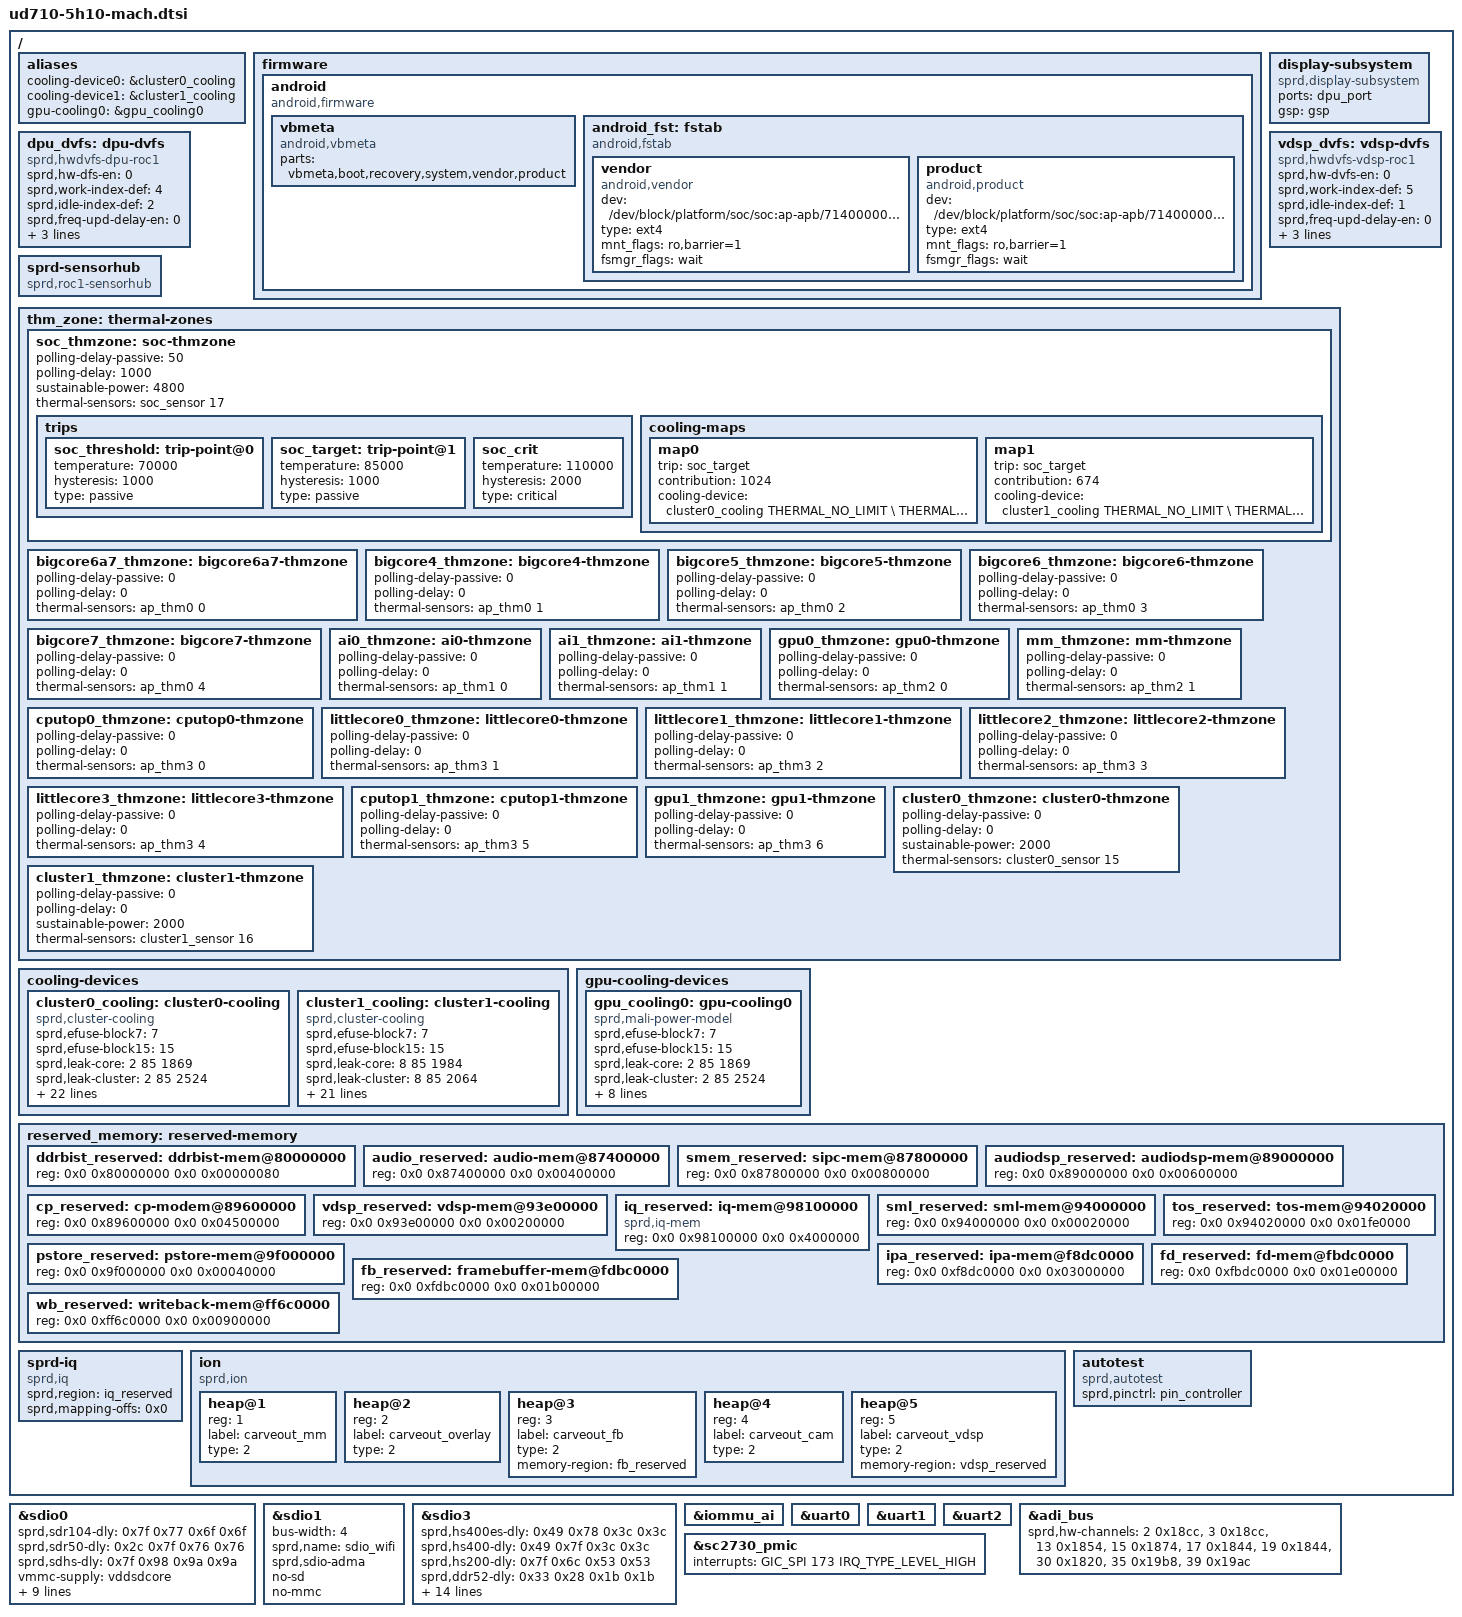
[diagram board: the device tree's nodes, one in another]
/*
 * Spreadtrum Roc1 board common DTS file
 *
 * Copyright (C) 2018, Spreadtrum Communications Inc.
 *
 * This file is licensed under a dual GPLv2 or X11 license.
 */

#include <dt-bindings/thermal/thermal.h>
/ {
	aliases {
		cooling-device0 = &cluster0_cooling;
		cooling-device1 = &cluster1_cooling;
		gpu-cooling0 = &gpu_cooling0;
	};

	firmware {
		android {
			compatible = "android,firmware";

			vbmeta {
				compatible = "android,vbmeta";
				parts = "vbmeta,boot,recovery,system,vendor,product";
			};

			android_fst: fstab {
				compatible = "android,fstab";
				vendor {
					compatible = "android,vendor";
					dev = "/dev/block/platform/soc/soc:ap-apb/71400000.sdio/by-name/vendor";
					type = "ext4";
					mnt_flags = "ro,barrier=1";
					fsmgr_flags = "wait";
				};
				product {
					compatible = "android,product";
					dev = "/dev/block/platform/soc/soc:ap-apb/71400000.sdio/by-name/product";
					type = "ext4";
					mnt_flags = "ro,barrier=1";
					fsmgr_flags = "wait";
				};
			};
		};
	};

	display-subsystem {
		compatible = "sprd,display-subsystem";
		ports = <&dpu_port>;
		gsp = <&gsp>;
	};

	dpu_dvfs: dpu-dvfs {
		compatible = "sprd,hwdvfs-dpu-roc1";
		sprd,hw-dfs-en = <0>;
		sprd,work-index-def = <4>;
		sprd,idle-index-def = <2>;
		sprd,freq-upd-delay-en = <0>;
		sprd,freq-upd-hdsk-en = <1>;

		operating-points = <
			/* kHz    uV */
			153600    700000
			192000    700000
			256000    700000
			307200    700000
			384000    750000
		>;
	};

	vdsp_dvfs: vdsp-dvfs {
		compatible = "sprd,hwdvfs-vdsp-roc1";
		sprd,hw-dvfs-en = <0>;
		sprd,work-index-def = <5>;
		sprd,idle-index-def = <1>;
		sprd,freq-upd-delay-en = <0>;
		sprd,freq-upd-hdsk-en = <1>;

		operating-points = <
			/* kHz    uV */
			192000    700000
			307200    700000
			468000    750000
			614400    800000
			702000    800000
			768000    800000
		>;
	};

	sprd-sensorhub {
		compatible = "sprd,roc1-sensorhub";
	};

	thm_zone: thermal-zones {

		soc_thmzone: soc-thmzone {
			polling-delay-passive = <50>;
			polling-delay = <1000>;
			sustainable-power = <4800>;
			thermal-sensors = <&soc_sensor  17>;
			trips {
				soc_threshold: trip-point@0 {
					temperature = <70000>;
					hysteresis = <1000>;
					type = "passive";
				};
				soc_target: trip-point@1 {
					temperature = <85000>;
					hysteresis = <1000>;
					type = "passive";
				};
				soc_crit: soc_crit {
					temperature = <110000>;
					hysteresis = <2000>;
					type = "critical";
				};
			};
			cooling-maps {
				map0 {
					trip = <&soc_target>;
					contribution = <1024>;
					cooling-device =
					<&cluster0_cooling THERMAL_NO_LIMIT \
					THERMAL_NO_LIMIT>;
				};
				map1 {
					trip = <&soc_target>;
					contribution = <674>;
					cooling-device =
					<&cluster1_cooling THERMAL_NO_LIMIT \
					THERMAL_NO_LIMIT>;
				};
			};
		};

		bigcore6a7_thmzone: bigcore6a7-thmzone {
			polling-delay-passive = <0>;
			polling-delay = <0>;
			thermal-sensors = <&ap_thm0 0>;
		};

		bigcore4_thmzone: bigcore4-thmzone {
			polling-delay-passive = <0>;
			polling-delay = <0>;
			thermal-sensors = <&ap_thm0 1>;
		};

		bigcore5_thmzone: bigcore5-thmzone {
			polling-delay-passive = <0>;
			polling-delay = <0>;
			thermal-sensors = <&ap_thm0 2>;
		};

		bigcore6_thmzone: bigcore6-thmzone {
			polling-delay-passive = <0>;
			polling-delay = <0>;
			thermal-sensors = <&ap_thm0 3>;
		};

		bigcore7_thmzone: bigcore7-thmzone {
			polling-delay-passive = <0>;
			polling-delay = <0>;
			thermal-sensors = <&ap_thm0 4>;
		};

		ai0_thmzone: ai0-thmzone {
			polling-delay-passive = <0>;
			polling-delay = <0>;
			thermal-sensors = <&ap_thm1 0>;
		};

		ai1_thmzone: ai1-thmzone {
			polling-delay-passive = <0>;
			polling-delay = <0>;
			thermal-sensors = <&ap_thm1 1>;
		};

		gpu0_thmzone: gpu0-thmzone {
			polling-delay-passive = <0>;
			polling-delay = <0>;
			thermal-sensors = <&ap_thm2 0>;
		};

		mm_thmzone: mm-thmzone {
			polling-delay-passive = <0>;
			polling-delay = <0>;
			thermal-sensors = <&ap_thm2 1>;
		};

		cputop0_thmzone: cputop0-thmzone {
			polling-delay-passive = <0>;
			polling-delay = <0>;
			thermal-sensors = <&ap_thm3 0>;
		};

		littlecore0_thmzone: littlecore0-thmzone {
			polling-delay-passive = <0>;
			polling-delay = <0>;
			thermal-sensors = <&ap_thm3 1>;
		};

		littlecore1_thmzone: littlecore1-thmzone {
			polling-delay-passive = <0>;
			polling-delay = <0>;
			thermal-sensors = <&ap_thm3 2>;
		};

		littlecore2_thmzone: littlecore2-thmzone {
			polling-delay-passive = <0>;
			polling-delay = <0>;
			thermal-sensors = <&ap_thm3 3>;
		};

		littlecore3_thmzone: littlecore3-thmzone {
			polling-delay-passive = <0>;
			polling-delay = <0>;
			thermal-sensors = <&ap_thm3 4>;
		};

		cputop1_thmzone: cputop1-thmzone {
			polling-delay-passive = <0>;
			polling-delay = <0>;
			thermal-sensors = <&ap_thm3 5>;
		};

		gpu1_thmzone: gpu1-thmzone {
			polling-delay-passive = <0>;
			polling-delay = <0>;
			thermal-sensors = <&ap_thm3 6>;
		};

		cluster0_thmzone: cluster0-thmzone {
			polling-delay-passive = <0>;
			polling-delay = <0>;
			sustainable-power = <2000>;
			thermal-sensors = <&cluster0_sensor  15>;
		};

		cluster1_thmzone: cluster1-thmzone {
			polling-delay-passive = <0>;
			polling-delay = <0>;
			sustainable-power = <2000>;
			thermal-sensors = <&cluster1_sensor  16>;
		};
	};

	cooling-devices {
		cluster0_cooling: cluster0-cooling {
			compatible = "sprd,cluster-cooling";
			#cooling-cells = <2>; /* min followed by max */
			sprd,efuse-block7 = <7>;
			sprd,efuse-block15 = <15>;
			/* core_leak =                             */
			/*(LIT_LEAK[4:0]+1) x 2mA x 0.85V x 18.69% */
			sprd,leak-core = <2 85 1869>;
			/* cluster_leak =                           */
			/* (LIT_LEAK[4:0]+1) x 2mA x 0.85V x 25.24% */
			sprd,leak-cluster = <2 85 2524>;
			/*core Tscale = aT^3 + bT^2 + cT +di   */
			sprd,core-temp-scale =
			/* a*10^7   b*10^7      c*10^7     d*10^7 */
			<  15      (-728)      70000    (-120000)>;
			/*core Vscale = eV^3 + fV^2 + gV + h */
			sprd,core-voltage-scale =
			/* e*10^2   f*10^2     g*10^2  h*10^2*/
			<  791     (-1867)      1581      (-405)>;
			/*cluster Tscale = aT^3 + bT^2 + cT +di   */
			sprd,cluster-temp-scale =
			/* a*10^7   b*10^7      c*10^7     d*10^7 */
			<  15      (-728)      70000    (-120000)>;
			/*cluster Vscale = eV^3 + fV^2 + gV + h */
			sprd,cluster-voltage-scale =
			/* e*10^2   f*10^2     g*10^2  h*10^2*/
			<  791     (-1867)      1581      (-405)>;
			sprd,efuse-switch = <0>;
			sprd,hotplug-period = <0>;
			sprd,min-cpufreq = <768000>;
			sprd,min-cpunum = <3>;
			sprd,core-base = <2778>;
			sprd,cluster-base = <3920>;
			sprd,dynamic-core =
			/*Pdynperghz*10    Freq     Vbase  */
			< 1178           1000     1000>;
			sprd,dynamic-cluster =
			/*Pdynperghz*10    Freq     Vbase  */
			< 11           1000     1000>;
			sprd,sensor-names = "littlecore0-thmzone",
				"littlecore1-thmzone",
				"littlecore2-thmzone",
				"littlecore3-thmzone";
			sprd,cii-per-core-tp = <105000 100000 95000 90000>;
			sprd,cii-max-tp-core = <90000>;
		};

		cluster1_cooling: cluster1-cooling {
			compatible = "sprd,cluster-cooling";
			#cooling-cells = <2>; /* min followed by max */
			sprd,efuse-block7 = <7>;
			sprd,efuse-block15 = <15>;
			/* core_leak =                             */
			/*(LIT_LEAK[4:0]+1) x 2mA x 0.85V x 18.69% */
			sprd,leak-core = <8 85 1984>;
			/* cluster_leak =                           */
			/* (LIT_LEAK[4:0]+1) x 2mA x 0.85V x 25.24% */
			sprd,leak-cluster = <8 85 2064>;
			/*core Tscale = aT^3 + bT^2 + cT +d  */
			sprd,core-temp-scale =
			/* a*10^7   b*10^7	c*10^7	   d*10^7*/
			<  15      (-728)      70000    (-120000)>;
			/* core  Vscale = eV^3 + fV^2 + gV + h */
			sprd,core-voltage-scale =
			/* e*10^2  f*10^2     g*10^2  h*10^2*/
			<  791     (-1867)      1581      (-405)>;
			/*cluster Tscale = aT^3 + bT^2 + cT +di   */
			sprd,cluster-temp-scale =
			/* a*10^7   b*10^7      c*10^7     d*10^7 */
			<  15      (-728)      70000    (-120000)>;
			/*cluster Vscale = eV^3 + fV^2 + gV + h */
			sprd,cluster-voltage-scale =
			/* e*10^2   f*10^2     g*10^2  h*10^2*/
			<  791     (-1867)      1581      (-405)>;
			sprd,efuse-switch = <0>;
			sprd,hotplug-period = <0>;
			sprd,min-cpufreq = <1228800>;
			sprd,min-cpunum = <0>;
			sprd,core-base = <9430>;
			sprd,cluster-base = <3920>;
			sprd,dynamic-core =
			/* Pdynperghz*10    Freq     Vbase */
			<  5571          1000     1000>;
			sprd,dynamic-cluster =
			/* Pdynperghz*10    Freq     Vbase */
			<  11            1000     1000>;
			sprd,sensor-names = "bigcore4-thmzone",
				"bigcore5-thmzone",
				"bigcore6-thmzone",
				"bigcore7-thmzone";
			sprd,cii-per-core-tp = <85000 80000 75000 70000>;
			sprd,cii-max-tp-core = <75000>;
		};
	};

	gpu-cooling-devices {
		gpu_cooling0: gpu-cooling0 {
			compatible = "sprd,mali-power-model";
			#cooling-cells = <2>;
			sprd,efuse-block7 = <7>;
			sprd,efuse-block15 = <15>;
			/* core_leak =                             */
			/*(LIT_LEAK[4:0]+1) x 2mA x 0.85V x 18.69% */
			sprd,leak-core = <2 85 1869>;
			/* cluster_leak =                           */
			/* (LIT_LEAK[4:0]+1) x 2mA x 0.85V x 25.24% */
			sprd,leak-cluster = <2 85 2524>;
			/*Tscale = aT^3 + bT^2 + cT +di   */
			sprd,temp-scale =
			/* a*10^7   b*10^7      c*10^7     d*10^7 */
			<  300     (-29000)     1491000    (-13962000)>;
			/*Vscale = eV^3 + fV^2 + gV + h */
			sprd,voltage-scale =
			/* e*10^2   f*10^2     g*10^2      h*10^2*/
			<  (-1629)  6627       (-6871)     2222>;
			sprd,hotplug-period = <0>;
			sprd,core-base = <966>;
			sprd,cluster-base = <966>;
			sprd,dynamic-core =
			/*Pdynperghz    Freq     Vbase  */
			< 6046           768     900>;
			sprd,dynamic-cluster =
			/*Pdynperghz    Freq     Vbase  */
			< 6064           768     900>;
		};
	};

	reserved_memory: reserved-memory {
		#address-cells = <2>;
		#size-cells = <2>;
		ranges;

		ddrbist_reserved: ddrbist-mem@80000000 {
			reg = <0x0 0x80000000 0x0 0x00000080>;
		};

		audio_reserved: audio-mem@87400000 {
			reg = <0x0 0x87400000 0x0 0x00400000>;
		};

		smem_reserved: sipc-mem@87800000 {
			reg = <0x0 0x87800000 0x0 0x00800000>;
		};

		audiodsp_reserved: audiodsp-mem@89000000 {
			reg = <0x0 0x89000000 0x0 0x00600000>;
		};

		cp_reserved: cp-modem@89600000 {
			reg = <0x0 0x89600000 0x0 0x04500000>;
		};

		vdsp_reserved: vdsp-mem@93e00000 {
			reg = <0x0 0x93e00000 0x0 0x00200000>;
		};

		/* Only used for iq, will be removed in normal mode by uboot */
		iq_reserved: iq-mem@98100000 {
			compatible = "sprd,iq-mem";
			reg = <0x0 0x98100000 0x0 0x4000000>;
		};

		sml_reserved: sml-mem@94000000 {
			reg = <0x0 0x94000000 0x0 0x00020000>;
		};

		tos_reserved: tos-mem@94020000 {
			reg = <0x0 0x94020000 0x0 0x01fe0000>;
		};

		pstore_reserved: pstore-mem@9f000000 {
			reg = <0x0 0x9f000000 0x0 0x00040000>;
		};

		ipa_reserved: ipa-mem@f8dc0000 {
			reg = <0x0 0xf8dc0000 0x0 0x03000000>;
		};

		fd_reserved: fd-mem@fbdc0000 {
			reg = <0x0 0xfbdc0000 0x0 0x01e00000>;
		};

		fb_reserved: framebuffer-mem@fdbc0000 {
			reg = <0x0 0xfdbc0000 0x0 0x01b00000>;
		};

		wb_reserved: writeback-mem@ff6c0000 {
			reg = <0x0 0xff6c0000 0x0 0x00900000>;
		};
	};

	sprd-iq {
			compatible = "sprd,iq";
			sprd,region = <&iq_reserved>;
			sprd,mapping-offs = <0x0>;
		};

	ion {
		compatible = "sprd,ion";
		#address-cells = <1>;
		#size-cells = <0>;

		heap@1 {
			reg = <1>;
			label = "carveout_mm";
			type = <2>;
		};

		heap@2 {
			reg = <2>;
			label = "carveout_overlay";
			type = <2>;
		};

		heap@3 {
			reg = <3>;
			label = "carveout_fb";
			type = <2>;
			memory-region = <&fb_reserved>;
		};

		heap@4 {
			reg = <4>;
			label = "carveout_cam";
			type = <2>;
		};

		heap@5 {
			reg = <5>;
			label = "carveout_vdsp";
			type = <2>;
			memory-region = <&vdsp_reserved>;
		};
	};

	autotest: autotest {
		compatible = "sprd,autotest";
		sprd,pinctrl = <&pin_controller>;
	};
};

&sdio0 {
	sprd,sdr104-dly=<0x7f 0x77 0x6f 0x6f>;
	sprd,sdr50-dly=<0x2c 0x7f 0x76 0x76>;
	sprd,sdhs-dly=<0x7f 0x98 0x9a 0x9a>;
	vmmc-supply = <&vddsdcore>;
	vqmmc-supply = <&vddsdio>;
	voltage-ranges = <3000 3000>;
	bus-width = <4>;
	sd-uhs-sdr104;
	sd-uhs-sdr50;
	sprd,name = "sdio_sd";
	sprd,sdio-adma;
	no-sdio;
	no-mmc;
	status = "okay";
};

&sdio1 {
	bus-width = <4>;
	sprd,name = "sdio_wifi";
	sprd,sdio-adma;
	no-sd;
	no-mmc;
	status = "okay";
};

&sdio3 {
	sprd,hs400es-dly=<0x49 0x78 0x3c 0x3c>;
	sprd,hs400-dly=<0x49 0x7f 0x3c 0x3c>;
	sprd,hs200-dly=<0x7f 0x6c 0x53 0x53>;
	sprd,ddr52-dly=<0x33 0x28 0x1b 0x1b>;
	sprd,mmchs-dly=<0x7f 0x95 0x7f 0x7f>;
	vmmc-supply = <&vddemmccore>;
	voltage-ranges = <3000 3000>;
	bus-width = <8>;
	non-removable;
	cap-mmc-hw-reset;
	mmc-hs400-enhanced-strobe;
	mmc-hs400-1_8v;
	mmc-hs200-1_8v;
	mmc-ddr-1_8v;
	sprd,name = "sdio_emmc";
	sprd,sdio-adma;
	no-sdio;
	no-sd;
	status = "okay";
};

&iommu_ai {
	status = "okay";
};

&uart0 {
	status = "okay";
};

&uart1 {
	status = "okay";
};

&uart2 {
	status = "okay";
};

&adi_bus {
	sprd,hw-channels = <2 0x18cc>, <3 0x18cc>, <13 0x1854>, <15 0x1874>, <17 0x1844>, <19 0x1844>, <30 0x1820>, <35 0x19b8>, <39 0x19ac>;
};

&sc2730_pmic {
	interrupts = <GIC_SPI 173 IRQ_TYPE_LEVEL_HIGH>;
};
